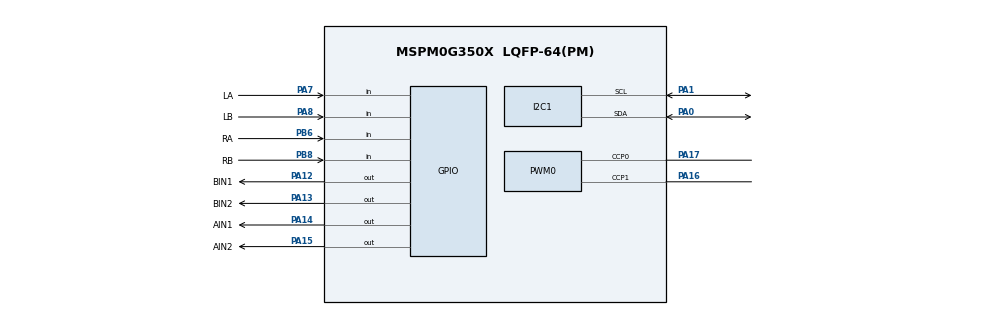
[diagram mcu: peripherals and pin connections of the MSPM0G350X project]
/**
 * @cliArgs --device "MSPM0G350X" --part "Default" --package "LQFP-64(PM)" --product "mspm0_sdk@2.10.00.04"
 * @versions {"tool":"1.26.2+4477"}
 */
const GPIO      = scripting.addModule("/ti/driverlib/GPIO", {}, false);
const I2C       = scripting.addModule("/ti/driverlib/I2C", {}, false);
const PWM       = scripting.addModule("/ti/driverlib/PWM", {}, false);
const TB6612    = GPIO.addInstance();
const ENCODER_L = GPIO.addInstance();
const ENCODER_R = GPIO.addInstance();
const I2C1      = I2C.addInstance();
const PWM0      = PWM.addInstance();
const SYSCTL    = scripting.addModule("/ti/driverlib/SYSCTL");

TB6612.$name                          = "TB6612";
TB6612.associatedPins.create(4);
TB6612.associatedPins[0].$name        = "AIN1";
TB6612.associatedPins[0].initialValue = "SET";
TB6612.associatedPins[0].pin.$assign  = "PA14";
TB6612.associatedPins[1].$name        = "AIN2";
TB6612.associatedPins[1].initialValue = "SET";
TB6612.associatedPins[1].pin.$assign  = "PA15";
TB6612.associatedPins[2].$name        = "BIN1";
TB6612.associatedPins[2].initialValue = "SET";
TB6612.associatedPins[2].pin.$assign  = "PA12";
TB6612.associatedPins[3].$name        = "BIN2";
TB6612.associatedPins[3].initialValue = "SET";
TB6612.associatedPins[3].pin.$assign  = "PA13";

ENCODER_L.$name                              = "ENCODER_L";
ENCODER_L.associatedPins.create(2);
ENCODER_L.associatedPins[0].$name            = "LA";
ENCODER_L.associatedPins[0].direction        = "INPUT";
ENCODER_L.associatedPins[0].internalResistor = "PULL_UP";
ENCODER_L.associatedPins[0].interruptEn      = true;
ENCODER_L.associatedPins[0].polarity         = "RISE";
ENCODER_L.associatedPins[0].pin.$assign      = "PA7";
ENCODER_L.associatedPins[1].$name            = "LB";
ENCODER_L.associatedPins[1].direction        = "INPUT";
ENCODER_L.associatedPins[1].internalResistor = "PULL_UP";
ENCODER_L.associatedPins[1].interruptEn      = true;
ENCODER_L.associatedPins[1].polarity         = "RISE";
ENCODER_L.associatedPins[1].pin.$assign      = "PA8";

ENCODER_R.$name                              = "ENCODER_R";
ENCODER_R.associatedPins.create(2);
ENCODER_R.associatedPins[0].$name            = "RA";
ENCODER_R.associatedPins[0].direction        = "INPUT";
ENCODER_R.associatedPins[0].internalResistor = "PULL_UP";
ENCODER_R.associatedPins[0].interruptEn      = true;
ENCODER_R.associatedPins[0].polarity         = "RISE";
ENCODER_R.associatedPins[0].pin.$assign      = "PB6";
ENCODER_R.associatedPins[1].$name            = "RB";
ENCODER_R.associatedPins[1].direction        = "INPUT";
ENCODER_R.associatedPins[1].internalResistor = "PULL_UP";
ENCODER_R.associatedPins[1].interruptEn      = true;
ENCODER_R.associatedPins[1].polarity         = "RISE";
ENCODER_R.associatedPins[1].pin.$assign      = "PB8";

I2C1.$name                       = "I2C";
I2C1.basicEnableController       = true;
I2C1.basicControllerBusSpeed     = 400000;
I2C1.advAnalogGlitchFilter       = "DISABLED";
I2C1.peripheral.sclPin.$assign   = "PA1";
I2C1.peripheral.sdaPin.$assign   = "PA0";

PWM0.$name                      = "PWM_0";
PWM0.clockPrescale              = 256;
PWM0.timerCount                 = 1000;
PWM0.pwmMode                    = "EDGE_ALIGN";
PWM0.peripheral.$assign         = "TIMA1";
PWM0.peripheral.ccp0Pin.$assign = "PA17";
PWM0.peripheral.ccp1Pin.$assign = "PA16";
PWM0.PWM_CHANNEL_0.$name        = "C0";
PWM0.PWM_CHANNEL_0.dutyCycle    = 0;
PWM0.PWM_CHANNEL_1.$name        = "C1";
PWM0.PWM_CHANNEL_1.dutyCycle    = 0;

const Board = scripting.addModule("/ti/driverlib/Board", {}, false);

SYSCTL.forceDefaultClkConfig = true;
Board.peripheral.$suggestSolution          = "DEBUGSS";
Board.peripheral.swclkPin.$suggestSolution = "PA20";
Board.peripheral.swdioPin.$suggestSolution = "PA19";
SYSCTL.peripheral.$suggestSolution         = "SYSCTL";
